# DMPAC0_HTS_S_VBUSP register map
Vendor: Texas Instruments
Registers are 32-bit, read-write, reset 0x0 unless marked. A register's access mark holds for its fields unless they carry their own. Offsets are as the file gives them; [hi:lo] are bit positions; {n}, {i} and the like mark numbered series; 'fields as' and 'values as' point back to an identical list.

## DMPAC0_HTS_S_VBUSP (part 2 of 2)
{0x0+4i} DMPAC_HTS_PIPELINE_CONTROL_{i} (i=0..6) — Enable pipeline to activate all connected scheduler
  [0] PIPE_EN — Pipeline {i} enable, writing '1' activate pipeline , writing '0' during active pipeline is illegal and behavior is undefined, read '1' -&gt; pipeline is active , read '0' -&gt; pipeline is inactive
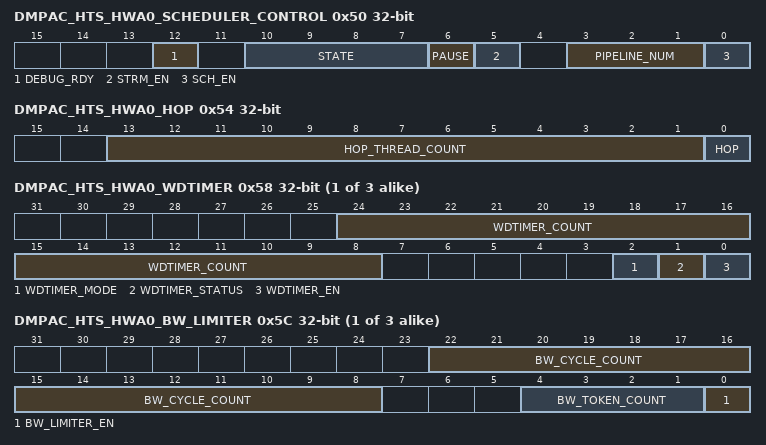
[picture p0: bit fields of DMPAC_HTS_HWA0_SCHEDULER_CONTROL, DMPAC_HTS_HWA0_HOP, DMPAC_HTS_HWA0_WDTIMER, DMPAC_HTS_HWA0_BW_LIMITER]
0x50 DMPAC_HTS_HWA0_SCHEDULER_CONTROL access per field — Scheduler Control Register
  [12] DEBUG_RDY rw — '0' -&gt; HWA0 Scheduler resources must not be read during halted state.'1'-&gt; HWA0 Scheduler resources are readable during halted state
  [10:7] STATE ro — Current state of HWA0 Scheduler
  [6] PAUSE rw — '1' -&gt; pause/suspend scheduler , '0' -&gt; resume scheduler
  [5] STRM_EN rw — '1' -&gt; Streaming input enable, '0' No streaming input
  [3:1] PIPELINE_NUM rw — Pipeline Number of HWA0 Scheduler
  [0] SCH_EN rw — scheduler enable write '1' to enable scheduler
0x54 DMPAC_HTS_HWA0_HOP — Scheduler HOP Control Register. Help in detecting eop within scheduler. Once configured, it counts task/channel starts and stops issuing further start. Specifically useful for Head of pipe dma scheduler .
  [13:1] HOP_THREAD_COUNT — Number of Task count for Head of pipe
  [0] HOP — '1' -&gt; Head of Pipe producer Sch , '0' -&gt; No hop
{0x58+0xB4*i} DMPAC_HTS_HWA{i}_WDTIMER access per field (i=0..2) — Watchdog timer control register
  [24:8] WDTIMER_COUNT ro — Current value of HWA{i} Scheduler watchdog timer count
  [2] WDTIMER_MODE rw — Watchdog timeout count '1' -&gt; 128K , '0' -&gt; 64K
  [1] WDTIMER_STATUS ro — HWA{i} Scheduler watchdog timer status '1' -&gt; Timer Active '0' -&gt; Timer Inactive (count is stable)
  [0] WDTIMER_EN rw — '1' -&gt; activate watchdog timer for 64K VPAC/DMPAC cycles between task start and task done '0' -&gt; Disable watchdog timer
{0x5C+0xB4*i} DMPAC_HTS_HWA{i}_BW_LIMITER (i=0..2) — Scheduler BW Control Register. Processing unit level BW control. Use DMA to eliminate peak system BW within processing units line/Block
  [22:8] BW_CYCLE_COUNT — Average Cycle count between successive Task Start
  [4:1] BW_TOKEN_COUNT — Max Token count to create average BW
  [0] BW_LIMITER_EN — '1' -&gt; Enable BW limiter function for HWA{i} sch, '0' --&gt; Disable
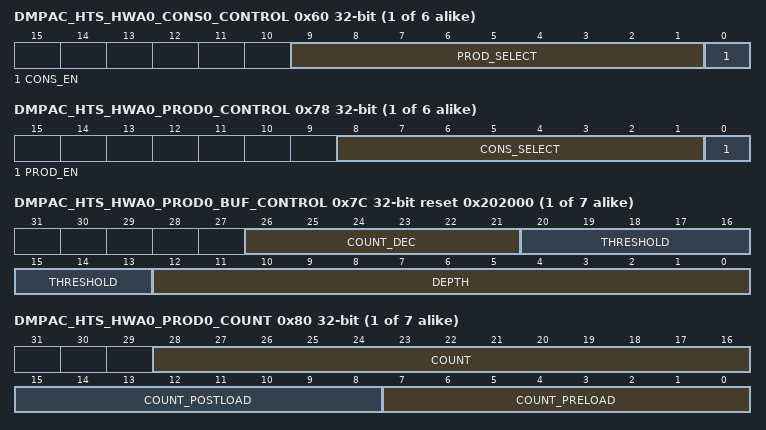
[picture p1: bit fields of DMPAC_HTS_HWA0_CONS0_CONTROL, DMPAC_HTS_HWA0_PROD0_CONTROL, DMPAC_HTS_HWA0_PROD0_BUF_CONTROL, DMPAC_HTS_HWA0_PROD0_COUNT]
{0x60+4i} DMPAC_HTS_HWA0_CONS{i}_CONTROL (i=0..5) — Controlling consumer socket {i} for HWA0
  [9:1] PROD_SELECT — producer select for HWA0 cons socket {i}
  [0] CONS_EN — '1' -&gt; Consumer socket {i} enable , '0' Disable
{0x78+0x14*i} DMPAC_HTS_HWA0_PROD{i}_CONTROL (i=0..5) — Controlling producer socket{i} for HWA0
  [8:1] CONS_SELECT — consumer select for HWA0 prod socket {i}.Used in decrementing count of producer buffer
  [0] PROD_EN — '1' -&gt; Producer socket 0 enable , '0' Disable
{0x7C+0x14*i} DMPAC_HTS_HWA0_PROD{i}_BUF_CONTROL reset 0x202000 (i=0..6) — Controlling producer socket{i} buffer for HWA0
  [26:21] COUNT_DEC — Count decrement value for prod count
  [20:13] THRESHOLD — Count threshold to generate pend for consumer
  [12:0] DEPTH — Maximum number of producer buffer count
{0x80+0x14*i} DMPAC_HTS_HWA0_PROD{i}_COUNT access per field (i=0..6) — Defining count values for pre/post load for generating pend by HWA0 prod{i}
  [28:16] COUNT ro — current count value
  [15:8] COUNT_POSTLOAD rw — count postload after producer max thread count reached
  [7:0] COUNT_PRELOAD rw — count preload after scheduler start/init
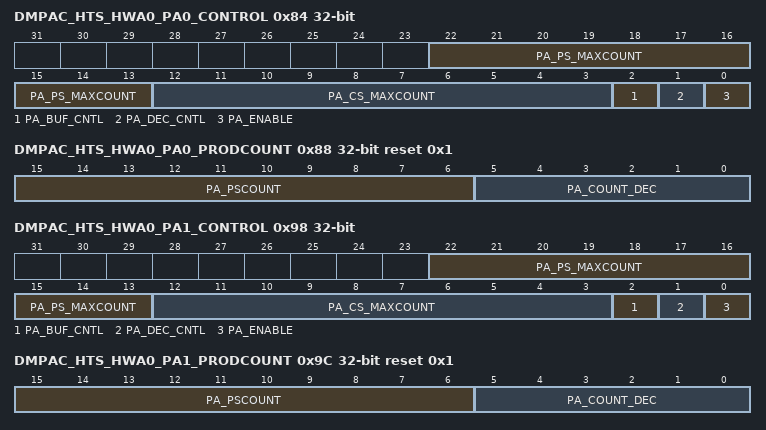
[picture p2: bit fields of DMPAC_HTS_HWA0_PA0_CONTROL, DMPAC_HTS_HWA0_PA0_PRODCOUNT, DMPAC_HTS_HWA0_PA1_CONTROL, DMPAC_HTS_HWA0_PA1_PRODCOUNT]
0x84 DMPAC_HTS_HWA0_PA0_CONTROL — control register to manage pattern adapter on HWA0 prod socket0
  [22:13] PA_PS_MAXCOUNT — destination count for pattern adaptation (N), M --&gt; N
  [12:3] PA_CS_MAXCOUNT — source count for pattern adaptation (M), M --&gt; N
  [2] PA_BUF_CNTL — '1' -&gt; Apply threshold, count_preload and count_postload on pattern adapter count (use this only when pa_enable='1') '0' -&gt; Apply threshold, count_preload and count_postload on prod count (same behavior as if no pattern adapter.Note when pa_enable='1' and pa_buf_cntl='0' threshold is not used and ignored)
  [1] PA_DEC_CNTL — '1' -&gt; post pattern adaptation, decrement ps count by count_dec , '0' -&gt; post pattern adaptation, decrement ps count by pa_cs_maxcount
  [0] PA_ENABLE — '1' -&gt; pa enable, '0' -&gt; disable
0x88 DMPAC_HTS_HWA0_PA0_PRODCOUNT access per field reset 0x1 — count values for HWA0 prod socket0
  [15:6] PA_PSCOUNT ro — current count value of pa prod count
  [5:0] PA_COUNT_DEC rw — Decrement count value of pa_prod_count after pattern adapter prod count reaches threshold
0x98 DMPAC_HTS_HWA0_PA1_CONTROL — control register to manage pattern adapter on HWA0 prod socket1
  fields as DMPAC_HTS_HWA0_PA0_CONTROL
0x9C DMPAC_HTS_HWA0_PA1_PRODCOUNT access per field reset 0x1 — count values for HWA0 prod socket1
  fields as DMPAC_HTS_HWA0_PA0_PRODCOUNT
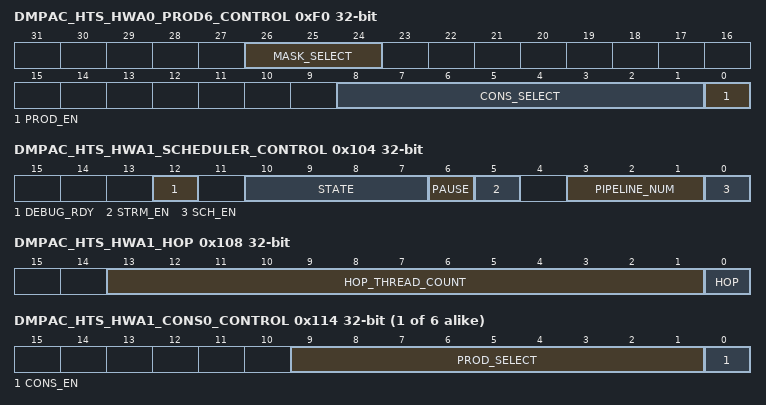
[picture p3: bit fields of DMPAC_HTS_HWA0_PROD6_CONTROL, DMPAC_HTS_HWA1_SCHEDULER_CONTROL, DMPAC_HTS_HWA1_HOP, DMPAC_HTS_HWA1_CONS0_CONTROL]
0xF0 DMPAC_HTS_HWA0_PROD6_CONTROL — Controlling producer socket6 for HWA0
  [26:24] MASK_SELECT — define which tdone_mask apply to prod socket 6.tdone_mask[mask_select] applies to prod_socket6
  [8:1] CONS_SELECT — consumer select for HWA0 prod socket 6.Used in decrementing count of producer buffer
  [0] PROD_EN — '1' -&gt; Producer socket 0 enable , '0' Disable
0x104 DMPAC_HTS_HWA1_SCHEDULER_CONTROL access per field — Scheduler Control Register
  [12] DEBUG_RDY rw — '0' -&gt; HWA1 Scheduler resources must not be read during halted state.'1'-&gt; HWA1 Scheduler resources are readable during halted state
  [10:7] STATE ro — Current state of HWA1 Scheduler
  [6] PAUSE rw — '1' -&gt; pause/suspend scheduler , '0' -&gt; resume scheduler
  [5] STRM_EN rw — '1' -&gt; Streaming input enable, '0' No streaming input
  [3:1] PIPELINE_NUM rw — Pipeline Number of HWA1 Scheduler
  [0] SCH_EN rw — scheduler enable write '1' to enable scheduler
0x108 DMPAC_HTS_HWA1_HOP — Scheduler HOP Control Register. Help in detecting eop within scheduler. Once configured, it counts task/channel starts and stops issuing further start. Specifically useful for Head of pipe dma scheduler .
  fields as DMPAC_HTS_HWA0_HOP
{0x114+4i} DMPAC_HTS_HWA1_CONS{i}_CONTROL (i=0..5) — Controlling consumer socket {i} for HWA1
  [9:1] PROD_SELECT — producer select for HWA1 cons socket {i}
  [0] CONS_EN — '1' -&gt; Consumer socket {i} enable , '0' Disable
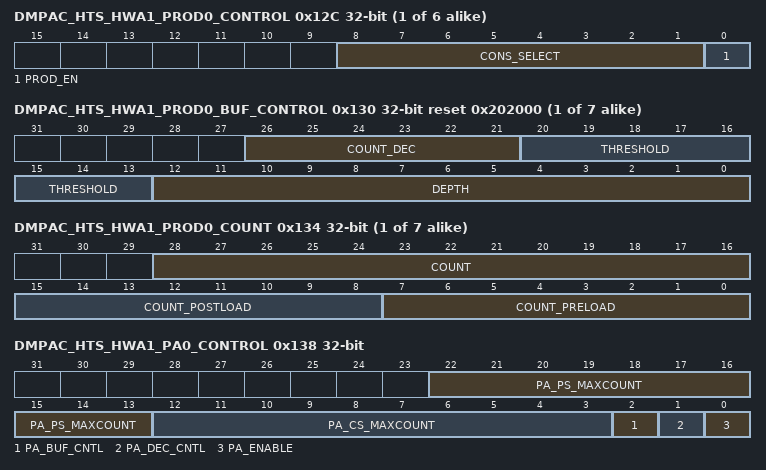
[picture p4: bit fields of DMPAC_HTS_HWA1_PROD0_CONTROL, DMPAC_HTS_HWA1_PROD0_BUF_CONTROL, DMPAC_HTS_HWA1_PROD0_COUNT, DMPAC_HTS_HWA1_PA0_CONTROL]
{0x12C+0x14*i} DMPAC_HTS_HWA1_PROD{i}_CONTROL (i=0..5) — Controlling producer socket{i} for HWA1
  [8:1] CONS_SELECT — consumer select for HWA1 prod socket {i}.Used in decrementing count of producer buffer
  [0] PROD_EN — '1' -&gt; Producer socket 0 enable , '0' Disable
{0x130+0x14*i} DMPAC_HTS_HWA1_PROD{i}_BUF_CONTROL reset 0x202000 (i=0..6) — Controlling producer socket{i} buffer for HWA1
  fields as DMPAC_HTS_HWA0_PROD0_BUF_CONTROL
{0x134+0x14*i} DMPAC_HTS_HWA1_PROD{i}_COUNT access per field (i=0..6) — Defining count values for pre/post load for generating pend by HWA1 prod{i}
  fields as DMPAC_HTS_HWA0_PROD0_COUNT
0x138 DMPAC_HTS_HWA1_PA0_CONTROL — control register to manage pattern adapter on HWA1 prod socket0
  fields as DMPAC_HTS_HWA0_PA0_CONTROL
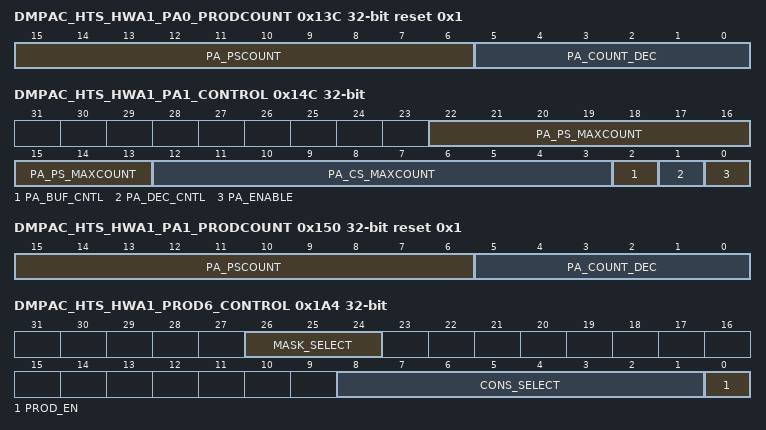
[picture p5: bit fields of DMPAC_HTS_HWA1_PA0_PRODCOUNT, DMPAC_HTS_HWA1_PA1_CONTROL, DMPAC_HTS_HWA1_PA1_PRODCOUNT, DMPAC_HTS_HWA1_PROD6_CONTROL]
0x13C DMPAC_HTS_HWA1_PA0_PRODCOUNT access per field reset 0x1 — count values for HWA1 prod socket0
  fields as DMPAC_HTS_HWA0_PA0_PRODCOUNT
0x14C DMPAC_HTS_HWA1_PA1_CONTROL — control register to manage pattern adapter on HWA1 prod socket1
  fields as DMPAC_HTS_HWA0_PA0_CONTROL
0x150 DMPAC_HTS_HWA1_PA1_PRODCOUNT access per field reset 0x1 — count values for HWA1 prod socket1
  fields as DMPAC_HTS_HWA0_PA0_PRODCOUNT
0x1A4 DMPAC_HTS_HWA1_PROD6_CONTROL — Controlling producer socket6 for HWA1
  [26:24] MASK_SELECT — define which tdone_mask apply to prod socket 6.tdone_mask[mask_select] applies to prod_socket6
  [8:1] CONS_SELECT — consumer select for HWA1 prod socket 6.Used in decrementing count of producer buffer
  [0] PROD_EN — '1' -&gt; Producer socket 0 enable , '0' Disable
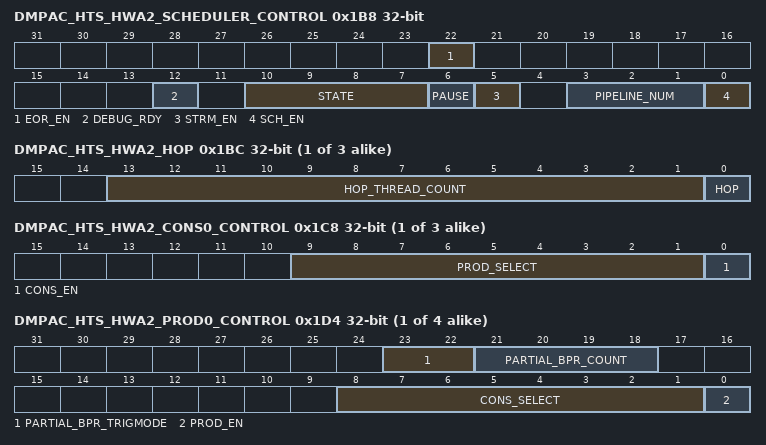
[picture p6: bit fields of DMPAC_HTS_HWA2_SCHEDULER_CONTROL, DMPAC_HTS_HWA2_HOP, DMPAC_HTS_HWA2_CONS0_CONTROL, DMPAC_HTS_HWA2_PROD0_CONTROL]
0x1B8 DMPAC_HTS_HWA2_SCHEDULER_CONTROL access per field — Scheduler Control Register
  [22] EOR_EN rw — '1' -&gt; LDC REGION/sub-frame feature enabled, '0' LDC works in Frame mode only
  [12] DEBUG_RDY rw — '0' -&gt; HWA2 Scheduler resources must not be read during halted state.'1'-&gt; HWA2 Scheduler resources are readable during halted state
  [10:7] STATE ro — Current state of HWA2 Scheduler
  [6] PAUSE rw — '1' -&gt; pause/suspend scheduler , '0' -&gt; resume scheduler
  [5] STRM_EN rw — '1' -&gt; Streaming input enable, '0' No streaming input
  [3:1] PIPELINE_NUM rw — Pipeline Number of HWA2 Scheduler
  [0] SCH_EN rw — scheduler enable write '1' to enable scheduler
{0x44+0xBC*i} DMPAC_HTS_HWA{i}_HOP (i=2..4) — Scheduler HOP Control Register. Help in detecting eop within scheduler. Once configured, it counts task/channel starts and stops issuing further starts. Specifically useful for Head of pipe dma scheduler .
  fields as DMPAC_HTS_HWA0_HOP
{0x1C8+4i} DMPAC_HTS_HWA2_CONS{i}_CONTROL (i=0..2) — Controlling consumer socket {i} for HWA2
  [9:1] PROD_SELECT — producer select for HWA2 cons socket {i}
  [0] CONS_EN — '1' -&gt; Consumer socket {i} enable , '0' Disable
{0x1D4+0x14*i} DMPAC_HTS_HWA2_PROD{i}_CONTROL (i=0..3) — Controlling producer socket{i} for HWA2
  [23:22] PARTIAL_BPR_TRIGMODE — 0: Normal behavior 1 : Prod Socket {i} is used to trigger DMA channel to transfer end of Row or End of Region Row buffer data for prod socket ({i}+2)%4. Useful when this Buffer is not completely filled at end of row and it enables triggering separate DMA channel for end of row. Rely on tdone_bpr_early attribute 2: Prod Socket {i} is used to trigger DMA channel to transfer end of Row or End of Region Row buffer data for prod socket ({i}+2)%4. Useful when this Buffer is not completely filled at end of row and it enables triggering separate DMA channel for end of row. Rely on end of Row attribute. Must not be used in dual output mode
  [21:18] PARTIAL_BPR_COUNT — Remaining block count to complete configured BPR at End of Row or End of Region Row when LDC is configured in tdone_gen_mode='0'
  [8:1] CONS_SELECT — consumer select for HWA2 prod socket {i}.Used in decrementing count of producer buffer
  [0] PROD_EN — '1' -&gt; Producer socket 0 enable , '0' Disable
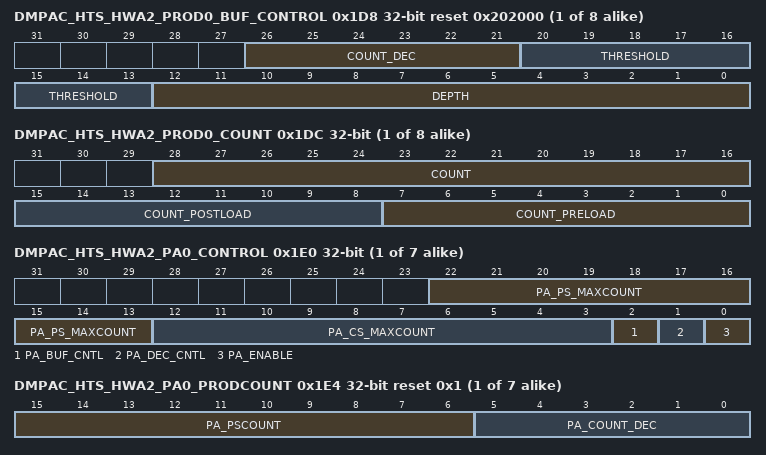
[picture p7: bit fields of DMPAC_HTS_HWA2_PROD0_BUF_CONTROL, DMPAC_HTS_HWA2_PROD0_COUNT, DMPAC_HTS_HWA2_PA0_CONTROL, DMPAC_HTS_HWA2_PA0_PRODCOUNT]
{0x1D8+0x14*i} DMPAC_HTS_HWA2_PROD{i}_BUF_CONTROL reset 0x202000 (i=0..7) — Controlling producer socket{i} buffer for HWA2
  fields as DMPAC_HTS_HWA0_PROD0_BUF_CONTROL
{0x1DC+0x14*i} DMPAC_HTS_HWA2_PROD{i}_COUNT access per field (i=0..7) — Defining count values for pre/post load for generating pend by HWA2 prod{i}
  fields as DMPAC_HTS_HWA0_PROD0_COUNT
{0x1E0+0x14*i} DMPAC_HTS_HWA2_PA{i}_CONTROL (i=0..6) — control register to manage pattern adapter on HWA2 prod socket{i}
  fields as DMPAC_HTS_HWA0_PA0_CONTROL
{0x1E4+0x14*i} DMPAC_HTS_HWA2_PA{i}_PRODCOUNT access per field reset 0x1 (i=0..6) — count values for HWA2 prod socket{i}
  fields as DMPAC_HTS_HWA0_PA0_PRODCOUNT
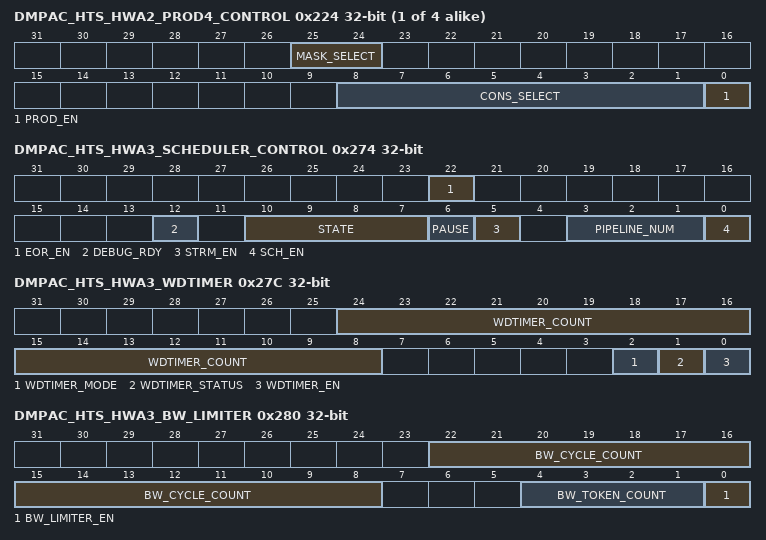
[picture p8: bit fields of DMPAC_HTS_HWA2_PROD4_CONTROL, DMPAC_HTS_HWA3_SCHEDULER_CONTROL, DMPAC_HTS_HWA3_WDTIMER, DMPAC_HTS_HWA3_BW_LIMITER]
{0x1D4+0x14*i} DMPAC_HTS_HWA2_PROD{i}_CONTROL (i=4..7) — Controlling producer socket{i} for HWA2
  [25:24] MASK_SELECT — define which tdone_mask apply to prod socket {i}.tdone_mask[mask_select] applies to prod_socket{i}.
  [8:1] CONS_SELECT — consumer select for HWA2 prod socket {i}.Used in decrementing count of producer buffer
  [0] PROD_EN — '1' -&gt; Producer socket 0 enable , '0' Disable
0x274 DMPAC_HTS_HWA3_SCHEDULER_CONTROL access per field — Scheduler Control Register
  [22] EOR_EN rw — '1' -&gt; LDC REGION/sub-frame feature enabled, '0' LDC works in Frame mode only
  [12] DEBUG_RDY rw — '0' -&gt; HWA3 Scheduler resources must not be read during halted state.'1'-&gt; HWA3 Scheduler resources are readable during halted state
  [10:7] STATE ro — Current state of HWA3 Scheduler
  [6] PAUSE rw — '1' -&gt; pause/suspend scheduler , '0' -&gt; resume scheduler
  [5] STRM_EN rw — '1' -&gt; Streaming input enable, '0' No streaming input
  [3:1] PIPELINE_NUM rw — Pipeline Number of HWA3 Scheduler
  [0] SCH_EN rw — scheduler enable write '1' to enable scheduler
0x27C DMPAC_HTS_HWA3_WDTIMER access per field — Watchdog timer control register
  [24:8] WDTIMER_COUNT ro — Current value of HWA3 Scheduler watchdog timer count
  [2] WDTIMER_MODE rw — Watchdog timeout count '1' -&gt; 128K , '0' -&gt; 64K
  [1] WDTIMER_STATUS ro — HWA3 Scheduler watchdog timer status '1' -&gt; Timer Active '0' -&gt; Timer Inactive (count is stable)
  [0] WDTIMER_EN rw — '1' -&gt; activate watchdog timer for 64K VPAC/DMPAC cycles between task start and task done '0' -&gt; Disable watchdog timer
0x280 DMPAC_HTS_HWA3_BW_LIMITER — Scheduler BW Control Register. Processing unit level BW control. Use DMA to eliminate peak system BW within processing units line/Block
  [22:8] BW_CYCLE_COUNT — Average Cycle count between successive Task Start
  [4:1] BW_TOKEN_COUNT — Max Token count to create average BW
  [0] BW_LIMITER_EN — '1' -&gt; Enable BW limiter function for HWA3 sch, '0' --&gt; Disable
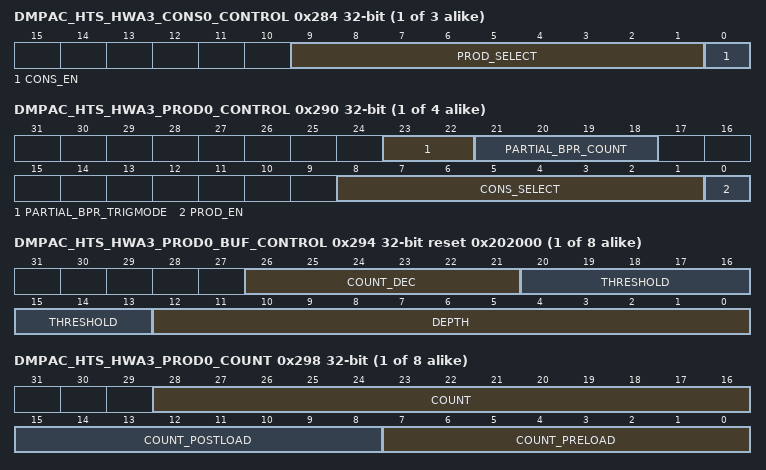
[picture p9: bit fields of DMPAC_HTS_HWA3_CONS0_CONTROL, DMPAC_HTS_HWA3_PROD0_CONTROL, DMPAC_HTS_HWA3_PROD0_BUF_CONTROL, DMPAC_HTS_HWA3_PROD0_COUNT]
{0x284+4i} DMPAC_HTS_HWA3_CONS{i}_CONTROL (i=0..2) — Controlling consumer socket {i} for HWA3
  [9:1] PROD_SELECT — producer select for HWA3 cons socket {i}
  [0] CONS_EN — '1' -&gt; Consumer socket {i} enable , '0' Disable
{0x290+0x14*i} DMPAC_HTS_HWA3_PROD{i}_CONTROL (i=0..3) — Controlling producer socket{i} for HWA3
  [23:22] PARTIAL_BPR_TRIGMODE — 0: Normal behavior 1 : Prod Socket {i} is used to trigger DMA channel to transfer end of Row or End of Region Row buffer data for prod socket ({i}+2)%4. Useful when this Buffer is not completely filled at end of row and it enables triggering separate DMA channel for end of row. Rely on tdone_bpr_early attribute 2: Prod Socket {i} is used to trigger DMA channel to transfer end of Row or End of Region Row buffer data for prod socket ({i}+2)%4. Useful when this Buffer is not completely filled at end of row and it enables triggering separate DMA channel for end of row. Rely on end of Row attribute. Must not be used in dual output mode
  [21:18] PARTIAL_BPR_COUNT — Remaining block count to complete configured BPR at End of Row or End of Region Row when LDC is configured in tdone_gen_mode='0'
  [8:1] CONS_SELECT — consumer select for HWA3 prod socket {i}.Used in decrementing count of producer buffer
  [0] PROD_EN — '1' -&gt; Producer socket 0 enable , '0' Disable
{0x294+0x14*i} DMPAC_HTS_HWA3_PROD{i}_BUF_CONTROL reset 0x202000 (i=0..7) — Controlling producer socket{i} buffer for HWA3
  fields as DMPAC_HTS_HWA0_PROD0_BUF_CONTROL
{0x298+0x14*i} DMPAC_HTS_HWA3_PROD{i}_COUNT access per field (i=0..7) — Defining count values for pre/post load for generating pend by HWA3 prod{i}
  fields as DMPAC_HTS_HWA0_PROD0_COUNT
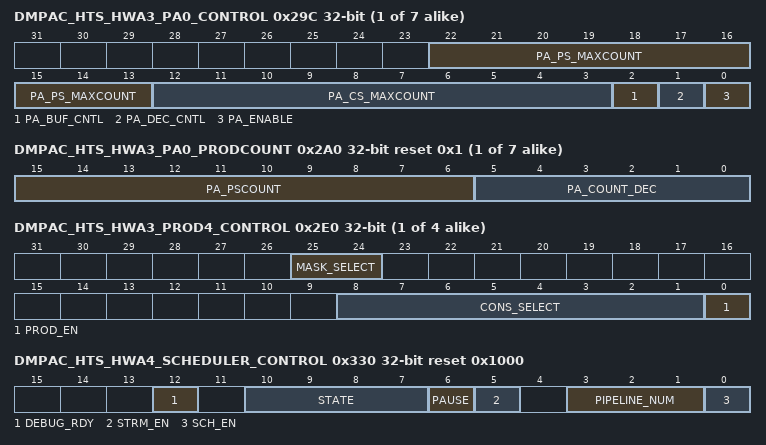
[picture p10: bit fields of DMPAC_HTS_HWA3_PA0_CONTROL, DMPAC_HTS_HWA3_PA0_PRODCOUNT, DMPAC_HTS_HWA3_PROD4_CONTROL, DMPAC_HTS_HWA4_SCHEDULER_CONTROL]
{0x29C+0x14*i} DMPAC_HTS_HWA3_PA{i}_CONTROL (i=0..6) — control register to manage pattern adapter on HWA3 prod socket{i}
  fields as DMPAC_HTS_HWA0_PA0_CONTROL
{0x2A0+0x14*i} DMPAC_HTS_HWA3_PA{i}_PRODCOUNT access per field reset 0x1 (i=0..6) — count values for HWA3 prod socket{i}
  fields as DMPAC_HTS_HWA0_PA0_PRODCOUNT
{0x290+0x14*i} DMPAC_HTS_HWA3_PROD{i}_CONTROL (i=4..7) — Controlling producer socket{i} for HWA3
  [25:24] MASK_SELECT — define which tdone_mask apply to prod socket {i}.tdone_mask[mask_select] applies to prod_socket{i}.
  [8:1] CONS_SELECT — consumer select for HWA3 prod socket {i}.Used in decrementing count of producer buffer
  [0] PROD_EN — '1' -&gt; Producer socket 0 enable , '0' Disable
0x330 DMPAC_HTS_HWA4_SCHEDULER_CONTROL access per field reset 0x1000 — Scheduler Control Register
  [12] DEBUG_RDY rw — '0' -&gt; HWA4 Scheduler resources must not be read during halted state.'1'-&gt; HWA4 Scheduler resources are readable during halted state
  [10:7] STATE ro — Current state of HWA4 Scheduler
  [6] PAUSE rw — '1' -&gt; pause/suspend scheduler , '0' -&gt; resume scheduler
  [5] STRM_EN rw — '1' -&gt; Streaming input enable, '0' No streaming input
  [3:1] PIPELINE_NUM rw — Pipeline Number of HWA4 Scheduler
  [0] SCH_EN rw — scheduler enable write '1' to enable scheduler
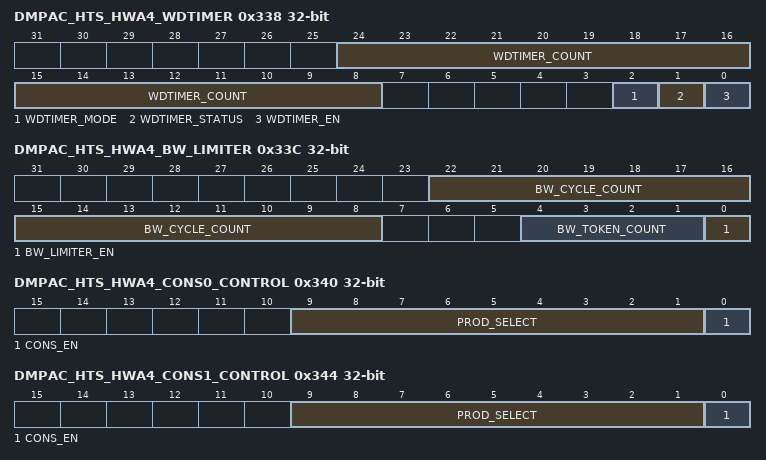
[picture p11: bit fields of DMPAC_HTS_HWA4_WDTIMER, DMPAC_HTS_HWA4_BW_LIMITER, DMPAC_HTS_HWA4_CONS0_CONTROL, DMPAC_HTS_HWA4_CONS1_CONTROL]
0x338 DMPAC_HTS_HWA4_WDTIMER access per field — Watchdog timer control register
  [24:8] WDTIMER_COUNT ro — Current value of HWA4 Scheduler watchdog timer count
  [2] WDTIMER_MODE rw — Watchdog timeout count '1' -&gt; 128K , '0' -&gt; 64K
  [1] WDTIMER_STATUS ro — HWA4 Scheduler watchdog timer status '1' -&gt; Timer Active '0' -&gt; Timer Inactive (count is stable)
  [0] WDTIMER_EN rw — '1' -&gt; activate watchdog timer for 64K VPAC/DMPAC cycles between task start and task done '0' -&gt; Disable watchdog timer
0x33C DMPAC_HTS_HWA4_BW_LIMITER — Scheduler BW Control Register. Processing unit level BW control. Use DMA to eliminate peak system BW within processing units line/Block
  [22:8] BW_CYCLE_COUNT — Average Cycle count between successive Task Start
  [4:1] BW_TOKEN_COUNT — Max Token count to create average BW
  [0] BW_LIMITER_EN — '1' -&gt; Enable BW limiter function for HWA4 sch, '0' --&gt; Disable
0x340 DMPAC_HTS_HWA4_CONS0_CONTROL — Controlling consumer socket 0 for HWA4
  [9:1] PROD_SELECT — producer select for HWA4 cons socket 0
  [0] CONS_EN — '1' -&gt; Consumer socket 0 enable , '0' Disable
0x344 DMPAC_HTS_HWA4_CONS1_CONTROL — Controlling consumer socket 1 for HWA4
  [9:1] PROD_SELECT — producer select for HWA4 cons socket 1
  [0] CONS_EN — '1' -&gt; Consumer socket 1 enable , '0' Disable
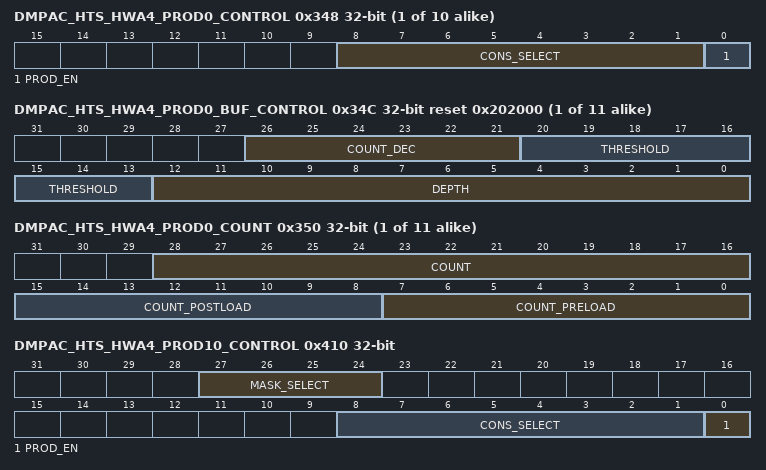
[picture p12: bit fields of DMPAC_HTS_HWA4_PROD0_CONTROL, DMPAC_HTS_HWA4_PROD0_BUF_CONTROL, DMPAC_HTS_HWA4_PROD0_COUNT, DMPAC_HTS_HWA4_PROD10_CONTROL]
{0x348+0x14*i} DMPAC_HTS_HWA4_PROD{i}_CONTROL (i=0..9) — Controlling producer socket{i} for HWA4
  [8:1] CONS_SELECT — consumer select for HWA4 prod socket {i}.Used in decrementing count of producer buffer
  [0] PROD_EN — '1' -&gt; Producer socket 0 enable , '0' Disable
{0x34C+0x14*i} DMPAC_HTS_HWA4_PROD{i}_BUF_CONTROL reset 0x202000 (i=0..10) — Controlling producer socket{i} buffer for HWA4
  fields as DMPAC_HTS_HWA0_PROD0_BUF_CONTROL
{0x350+0x14*i} DMPAC_HTS_HWA4_PROD{i}_COUNT access per field (i=0..10) — Defining count values for pre/post load for generating pend by HWA4 prod{i}
  fields as DMPAC_HTS_HWA0_PROD0_COUNT
0x410 DMPAC_HTS_HWA4_PROD10_CONTROL — Controlling producer socket10 for HWA4
  [27:24] MASK_SELECT — define which tdone_mask apply to prod socket 10.tdone_mask[mask_select] applies to prod_socket10
  [8:1] CONS_SELECT — consumer select for HWA4 prod socket 10.Used in decrementing count of producer buffer
  [0] PROD_EN — '1' -&gt; Producer socket 0 enable , '0' Disable
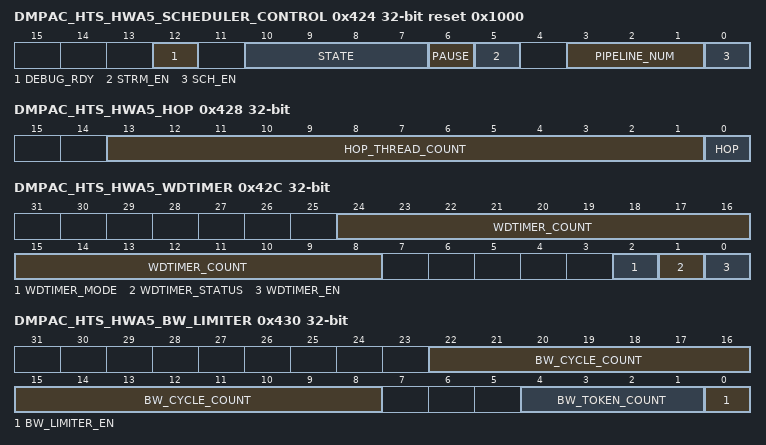
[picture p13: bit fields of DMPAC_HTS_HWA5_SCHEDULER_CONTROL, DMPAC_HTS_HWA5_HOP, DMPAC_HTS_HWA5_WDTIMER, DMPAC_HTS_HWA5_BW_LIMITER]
0x424 DMPAC_HTS_HWA5_SCHEDULER_CONTROL access per field reset 0x1000 — Scheduler Control Register
  [12] DEBUG_RDY rw — '0' -&gt; HWA5 Scheduler resources must not be read during halted state.'1'-&gt; HWA5 Scheduler resources are readable during halted state
  [10:7] STATE ro — Current state of HWA5 Scheduler
  [6] PAUSE rw — '1' -&gt; pause/suspend scheduler , '0' -&gt; resume scheduler
  [5] STRM_EN rw — '1' -&gt; Streaming input enable, '0' No streaming input
  [3:1] PIPELINE_NUM rw — Pipeline Number of HWA5 Scheduler
  [0] SCH_EN rw — scheduler enable write '1' to enable scheduler
0x428 DMPAC_HTS_HWA5_HOP — Scheduler HOP Control Register. Help in detecting eop within scheduler. Once configured, it counts task/channel starts and stops issuing further starts. Specifically useful for Head of pipe dma scheduler .
  fields as DMPAC_HTS_HWA0_HOP
0x42C DMPAC_HTS_HWA5_WDTIMER access per field — Watchdog timer control register
  [24:8] WDTIMER_COUNT ro — Current value of HWA5 Scheduler watchdog timer count
  [2] WDTIMER_MODE rw — Watchdog timeout count '1' -&gt; 128K , '0' -&gt; 64K
  [1] WDTIMER_STATUS ro — HWA5 Scheduler watchdog timer status '1' -&gt; Timer Active '0' -&gt; Timer Inactive (count is stable)
  [0] WDTIMER_EN rw — '1' -&gt; activate watchdog timer for 64K VPAC/DMPAC cycles between task start and task done '0' -&gt; Disable watchdog timer
0x430 DMPAC_HTS_HWA5_BW_LIMITER — Scheduler BW Control Register. Processing unit level BW control. Use DMA to eliminate peak system BW within processing units line/Block
  [22:8] BW_CYCLE_COUNT — Average Cycle count between successive Task Start
  [4:1] BW_TOKEN_COUNT — Max Token count to create average BW
  [0] BW_LIMITER_EN — '1' -&gt; Enable BW limiter function for HWA5 sch, '0' --&gt; Disable
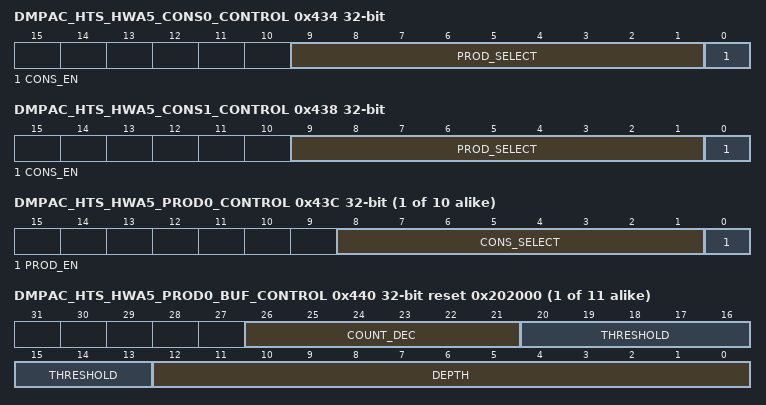
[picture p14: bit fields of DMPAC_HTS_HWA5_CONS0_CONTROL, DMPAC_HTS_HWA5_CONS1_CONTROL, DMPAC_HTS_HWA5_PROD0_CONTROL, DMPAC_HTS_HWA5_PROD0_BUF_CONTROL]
0x434 DMPAC_HTS_HWA5_CONS0_CONTROL — Controlling consumer socket 0 for HWA5
  [9:1] PROD_SELECT — producer select for HWA5 cons socket 0
  [0] CONS_EN — '1' -&gt; Consumer socket 0 enable , '0' Disable
0x438 DMPAC_HTS_HWA5_CONS1_CONTROL — Controlling consumer socket 1 for HWA5
  [9:1] PROD_SELECT — producer select for HWA5 cons socket 1
  [0] CONS_EN — '1' -&gt; Consumer socket 1 enable , '0' Disable
{0x43C+0x14*i} DMPAC_HTS_HWA5_PROD{i}_CONTROL (i=0..9) — Controlling producer socket{i} for HWA5
  [8:1] CONS_SELECT — consumer select for HWA5 prod socket {i}.Used in decrementing count of producer buffer
  [0] PROD_EN — '1' -&gt; Producer socket 0 enable , '0' Disable
{0x440+0x14*i} DMPAC_HTS_HWA5_PROD{i}_BUF_CONTROL reset 0x202000 (i=0..10) — Controlling producer socket{i} buffer for HWA5
  fields as DMPAC_HTS_HWA0_PROD0_BUF_CONTROL
{0x444+0x14*i} DMPAC_HTS_HWA5_PROD{i}_COUNT access per field (i=0..10) — Defining count values for pre/post load for generating pend by HWA5 prod{i}
  fields as DMPAC_HTS_HWA0_PROD0_COUNT
0x504 DMPAC_HTS_HWA5_PROD10_CONTROL — Controlling producer socket10 for HWA5
  [27:24] MASK_SELECT — define which tdone_mask apply to prod socket 10.tdone_mask[mask_select] applies to prod_socket10
  [8:1] CONS_SELECT — consumer select for HWA5 prod socket 10.Used in decrementing count of producer buffer
  [0] PROD_EN — '1' -&gt; Producer socket 0 enable , '0' Disable
0x518 DMPAC_HTS_HWA6_SCHEDULER_CONTROL access per field reset 0x1000 — Scheduler Control Register
  [12] DEBUG_RDY rw — '0' -&gt; HWA6 Scheduler resources must not be read during halted state.'1'-&gt; HWA6 Scheduler resources are readable during halted state
  [10:7] STATE ro — Current state of HWA6 Scheduler
  [6] PAUSE rw — '1' -&gt; pause/suspend scheduler , '0' -&gt; resume scheduler
  [5] STRM_EN rw — '1' -&gt; Streaming input enable, '0' No streaming input
  [3:1] PIPELINE_NUM rw — Pipeline Number of HWA6 Scheduler
  [0] SCH_EN rw — scheduler enable write '1' to enable scheduler
0x51C DMPAC_HTS_HWA6_HOP — Scheduler HOP Control Register. Help in detecting eop within scheduler. Once configured, it counts task/channel starts and stops issuing further starts. Specifically useful for Head of pipe dma scheduler .
  fields as DMPAC_HTS_HWA0_HOP
0x520 DMPAC_HTS_HWA6_WDTIMER access per field — Watchdog timer control register
  [24:8] WDTIMER_COUNT ro — Current value of HWA6 Scheduler watchdog timer count
  [2] WDTIMER_MODE rw — Watchdog timeout count '1' -&gt; 128K , '0' -&gt; 64K
  [1] WDTIMER_STATUS ro — HWA6 Scheduler watchdog timer status '1' -&gt; Timer Active '0' -&gt; Timer Inactive (count is stable)
  [0] WDTIMER_EN rw — '1' -&gt; activate watchdog timer for 64K VPAC/DMPAC cycles between task start and task done '0' -&gt; Disable watchdog timer
0x524 DMPAC_HTS_HWA6_BW_LIMITER — Scheduler BW Control Register. Processing unit level BW control. Use DMA to eliminate peak system BW within processing units line/Block
  [22:8] BW_CYCLE_COUNT — Average Cycle count between successive Task Start
  [4:1] BW_TOKEN_COUNT — Max Token count to create average BW
  [0] BW_LIMITER_EN — '1' -&gt; Enable BW limiter function for HWA6 sch, '0' --&gt; Disable
0x528 DMPAC_HTS_HWA6_CONS0_CONTROL — Controlling consumer socket 0 for HWA6
  [9:1] PROD_SELECT — producer select for HWA6 cons socket 0
  [0] CONS_EN — '1' -&gt; Consumer socket 0 enable , '0' Disable
0x52C DMPAC_HTS_HWA6_CONS1_CONTROL — Controlling consumer socket 1 for HWA6
  [9:1] PROD_SELECT — producer select for HWA6 cons socket 1
  [0] CONS_EN — '1' -&gt; Consumer socket 1 enable , '0' Disable
0x530 DMPAC_HTS_HWA6_PROD0_CONTROL — Controlling producer socket0 for HWA6
  [8:1] CONS_SELECT — consumer select for HWA6 prod socket 0.Used in decrementing count of producer buffer
  [0] PROD_EN — '1' -&gt; Producer socket 0 enable , '0' Disable
0x534 DMPAC_HTS_HWA6_PROD0_BUF_CONTROL reset 0x202000 — Controlling producer socket0 buffer for HWA6
  fields as DMPAC_HTS_HWA0_PROD0_BUF_CONTROL
0x538 DMPAC_HTS_HWA6_PROD0_COUNT access per field — Defining count values for pre/post load for generating pend by HWA6 prod0
  fields as DMPAC_HTS_HWA0_PROD0_COUNT
0x544 DMPAC_HTS_HWA6_PROD1_CONTROL — Controlling producer socket1 for HWA6
  [8:1] CONS_SELECT — consumer select for HWA6 prod socket 1.Used in decrementing count of producer buffer
  [0] PROD_EN — '1' -&gt; Producer socket 0 enable , '0' Disable
0x548 DMPAC_HTS_HWA6_PROD1_BUF_CONTROL reset 0x202000 — Controlling producer socket1 buffer for HWA6
  fields as DMPAC_HTS_HWA0_PROD0_BUF_CONTROL
0x54C DMPAC_HTS_HWA6_PROD1_COUNT access per field — Defining count values for pre/post load for generating pend by HWA6 prod1
  fields as DMPAC_HTS_HWA0_PROD0_COUNT
0x558 DMPAC_HTS_HWA7_SCHEDULER_CONTROL access per field reset 0x1000 — Scheduler Control Register
  [12] DEBUG_RDY rw — '0' -&gt; HWA7 Scheduler resources must not be read during halted state.'1'-&gt; HWA7 Scheduler resources are readable during halted state
  [10:7] STATE ro — Current state of HWA7 Scheduler
  [6] PAUSE rw — '1' -&gt; pause/suspend scheduler , '0' -&gt; resume scheduler
  [5] STRM_EN rw — '1' -&gt; Streaming input enable, '0' No streaming input
  [3:1] PIPELINE_NUM rw — Pipeline Number of HWA7 Scheduler
  [0] SCH_EN rw — scheduler enable write '1' to enable scheduler
0x55C DMPAC_HTS_HWA7_HOP — Scheduler HOP Control Register. Help in detecting eop within scheduler. Once configured, it counts task/channel starts and stops issuing further start. Specifically useful for Head of pipe dma scheduler .
  fields as DMPAC_HTS_HWA0_HOP
0x560 DMPAC_HTS_HWA7_WDTIMER access per field — Watchdog timer control register
  [24:8] WDTIMER_COUNT ro — Current value of HWA7 Scheduler watchdog timer count
  [2] WDTIMER_MODE rw — Watchdog timeout count '1' -&gt; 128K , '0' -&gt; 64K
  [1] WDTIMER_STATUS ro — HWA7 Scheduler watchdog timer status '1' -&gt; Timer Active '0' -&gt; Timer Inactive (count is stable)
  [0] WDTIMER_EN rw — '1' -&gt; activate watchdog timer for 64K VPAC/DMPAC cycles between task start and task done '0' -&gt; Disable watchdog timer
0x564 DMPAC_HTS_HWA7_BW_LIMITER — Scheduler BW Control Register. Processing unit level BW control. Use DMA to eliminate peak system BW within processing units line/Block
  [22:8] BW_CYCLE_COUNT — Average Cycle count between successive Task Start
  [4:1] BW_TOKEN_COUNT — Max Token count to create average BW
  [0] BW_LIMITER_EN — '1' -&gt; Enable BW limiter function for HWA7 sch, '0' --&gt; Disable
{0x568+4i} DMPAC_HTS_HWA7_CONS{i}_CONTROL (i=0..4) — Controlling consumer socket {i} for HWA7
  [9:1] PROD_SELECT — producer select for HWA7 cons socket {i}
  [0] CONS_EN — '1' -&gt; Consumer socket {i} enable , '0' Disable
{0x57C+0x14*i} DMPAC_HTS_HWA7_PROD{i}_CONTROL (i=0..3) — Controlling producer socket{i} for HWA7
  [8:1] CONS_SELECT — consumer select for HWA7 prod socket {i}.Used in decrementing count of producer buffer
  [0] PROD_EN — '1' -&gt; Producer socket 0 enable , '0' Disable
{0x580+0x14*i} DMPAC_HTS_HWA7_PROD{i}_BUF_CONTROL reset 0x202000 (i=0..4) — Controlling producer socket{i} buffer for HWA7
  fields as DMPAC_HTS_HWA0_PROD0_BUF_CONTROL
{0x584+0x14*i} DMPAC_HTS_HWA7_PROD{i}_COUNT access per field (i=0..4) — Defining count values for pre/post load for generating pend by HWA7 prod{i}
  fields as DMPAC_HTS_HWA0_PROD0_COUNT
{0x588+0x14*i} DMPAC_HTS_HWA7_PA{i}_CONTROL (i=0..3) — control register to manage pattern adapter on HWA7 prod socket{i}
  fields as DMPAC_HTS_HWA0_PA0_CONTROL
{0x58C+0x14*i} DMPAC_HTS_HWA7_PA{i}_PRODCOUNT access per field reset 0x1 (i=0..3) — count values for HWA7 prod socket{i}
  fields as DMPAC_HTS_HWA0_PA0_PRODCOUNT
0x5CC DMPAC_HTS_HWA7_PROD4_CONTROL — Controlling producer socket4 for HWA7
  [25:24] MASK_SELECT — define which tdone_mask apply to prod socket 4.tdone_mask[mask_select] applies to prod_socket4
  [8:1] CONS_SELECT — consumer select for HWA7 prod socket 4.Used in decrementing count of producer buffer
  [0] PROD_EN — '1' -&gt; Producer socket 0 enable , '0' Disable
0x5E0 DMPAC_HTS_HWA8_SCHEDULER_CONTROL access per field reset 0x1000 — Scheduler Control Register
  [12] DEBUG_RDY rw — '0' -&gt; HWA8 Scheduler resources must not be read during halted state.'1'-&gt; HWA8 Scheduler resources are readable during halted state
  [10:7] STATE ro — Current state of HWA8 Scheduler
  [6] PAUSE rw — '1' -&gt; pause/suspend scheduler , '0' -&gt; resume scheduler
  [5] STRM_EN rw — '1' -&gt; Streaming input enable, '0' No streaming input
  [3:1] PIPELINE_NUM rw — Pipeline Number of HWA8 Scheduler
  [0] SCH_EN rw — scheduler enable write '1' to enable scheduler
0x5E4 DMPAC_HTS_HWA8_HOP — Scheduler HOP Control Register. Help in detecting eop within scheduler. Once configured, it counts task/channel starts and stops issuing further start. Specifically useful for Head of pipe dma scheduler .
  fields as DMPAC_HTS_HWA0_HOP
0x5E8 DMPAC_HTS_HWA8_WDTIMER access per field — Watchdog timer control register
  [24:8] WDTIMER_COUNT ro — Current value of HWA8 Scheduler watchdog timer count
  [2] WDTIMER_MODE rw — Watchdog timeout count '1' -&gt; 128K , '0' -&gt; 64K
  [1] WDTIMER_STATUS ro — HWA8 Scheduler watchdog timer status '1' -&gt; Timer Active '0' -&gt; Timer Inactive (count is stable)
  [0] WDTIMER_EN rw — '1' -&gt; activate watchdog timer for 64K VPAC/DMPAC cycles between task start and task done '0' -&gt; Disable watchdog timer
0x5EC DMPAC_HTS_HWA8_BW_LIMITER — Scheduler BW Control Register. Processing unit level BW control. Use DMA to eliminate peak system BW within processing units line/Block
  [22:8] BW_CYCLE_COUNT — Average Cycle count between successive Task Start
  [4:1] BW_TOKEN_COUNT — Max Token count to create average BW
  [0] BW_LIMITER_EN — '1' -&gt; Enable BW limiter function for HWA8 sch, '0' --&gt; Disable
{0x5F0+4i} DMPAC_HTS_HWA8_CONS{i}_CONTROL (i=0..4) — Controlling consumer socket {i} for HWA8
  [9:1] PROD_SELECT — producer select for HWA8 cons socket {i}
  [0] CONS_EN — '1' -&gt; Consumer socket {i} enable , '0' Disable
{0x604+0x14*i} DMPAC_HTS_HWA8_PROD{i}_CONTROL (i=0..3) — Controlling producer socket{i} for HWA8
  [8:1] CONS_SELECT — consumer select for HWA8 prod socket {i}.Used in decrementing count of producer buffer
  [0] PROD_EN — '1' -&gt; Producer socket 0 enable , '0' Disable
{0x608+0x14*i} DMPAC_HTS_HWA8_PROD{i}_BUF_CONTROL reset 0x202000 (i=0..4) — Controlling producer socket{i} buffer for HWA8
  fields as DMPAC_HTS_HWA0_PROD0_BUF_CONTROL
{0x60C+0x14*i} DMPAC_HTS_HWA8_PROD{i}_COUNT access per field (i=0..4) — Defining count values for pre/post load for generating pend by HWA8 prod{i}
  fields as DMPAC_HTS_HWA0_PROD0_COUNT
{0x610+0x14*i} DMPAC_HTS_HWA8_PA{i}_CONTROL (i=0..3) — control register to manage pattern adapter on HWA8 prod socket{i}
  fields as DMPAC_HTS_HWA0_PA0_CONTROL
{0x614+0x14*i} DMPAC_HTS_HWA8_PA{i}_PRODCOUNT access per field reset 0x1 (i=0..3) — count values for HWA8 prod socket{i}
  fields as DMPAC_HTS_HWA0_PA0_PRODCOUNT
0x654 DMPAC_HTS_HWA8_PROD4_CONTROL — Controlling producer socket4 for HWA8
  [25:24] MASK_SELECT — define which tdone_mask apply to prod socket 4.tdone_mask[mask_select] applies to prod_socket4
  [8:1] CONS_SELECT — consumer select for HWA8 prod socket 4.Used in decrementing count of producer buffer
  [0] PROD_EN — '1' -&gt; Producer socket 0 enable , '0' Disable
{0x188+0x68*i} DMPAC_HTS_HWA{i}_SCHEDULER_CONTROL access per field reset 0x1000 (i=12..19) — Scheduler Control Register
  [23] START_LOOP_BACK rw — '1' -&gt; loop back start onto done in same cycle w/o asserting external channel start, '0' No loop back
  [20:13] DMA_CHANNEL_NO rw — DMA channel number for thread scheduler for HWA{i}
  [12] DEBUG_RDY rw — '0' -&gt; HWA{i} Scheduler resources must not be read during halted state.'1'-&gt; HWA{i} Scheduler resources are readable during halted state
  [10:7] STATE ro — Current state of HWA{i} Scheduler
  [6] PAUSE rw — '1' -&gt; pause/suspend scheduler , '0' -&gt; resume scheduler
  [5] STRM_EN rw — '1' -&gt; Streaming input enable, '0' No streaming input
  [3:1] PIPELINE_NUM rw — Pipeline Number of HWA{i} Scheduler
  [0] SCH_EN rw — scheduler enable write '1' to enable scheduler
